# NAVSS0_SEC_PROXY_0_ALIAS64K_SEC_PROXY0_CFG_SCFG register map
Vendor: Texas Instruments
Peripheral module from a debugger description file (folder J7_AHP).
Registers are 32-bit, read-write, reset 0x0 unless marked. A register's access mark holds for its fields unless they carry their own. Offsets are as the file gives them; lines under a group give offsets from that group; [hi:lo] are bit positions; {n}, {i} and the like mark numbered series; 'fields as' and 'values as' point back to an identical list; <NAME> marks a mode.

## NAVSS0_SEC_PROXY_0_ALIAS64K_SEC_PROXY0_CFG_SCFG
0x00 ALIAS64K_SEC_PROXY0__CFG__SCFG_buffer_l
  [31:0] BASE_L — The base address for the external buffer, lower 32 bits.
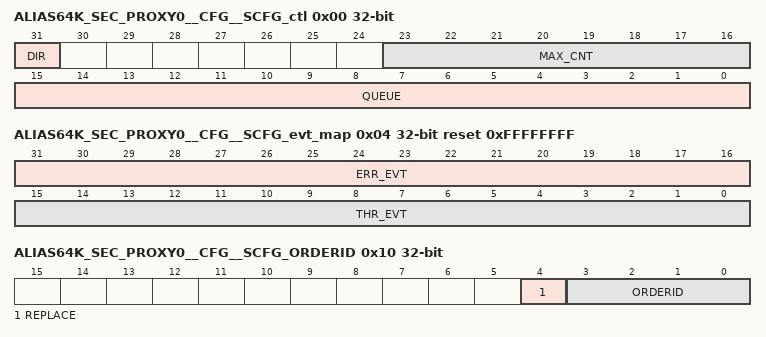
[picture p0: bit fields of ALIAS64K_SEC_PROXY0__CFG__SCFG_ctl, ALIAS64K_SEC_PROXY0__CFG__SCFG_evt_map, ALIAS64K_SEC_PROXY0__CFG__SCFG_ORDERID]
0x00 ALIAS64K_SEC_PROXY0__CFG__SCFG_ctl
  [31] DIR — Direction for the proxy thread. 0 = outbound, write only. 1 = inbound, read only.
  [23:16] MAX_CNT — Max message count allowed for an outbound proxy thread. Is not used otherwise.
  [15:0] QUEUE — Queue number in the target to use for the proxy thread. If the target base does not start at queue 0 then this is the relative queue number from that base queue.
0x04 ALIAS64K_SEC_PROXY0__CFG__SCFG_buffer_h
  [15:0] BASE_H — The base address for the external buffer, upper 16 bits.
0x04 ALIAS64K_SEC_PROXY0__CFG__SCFG_evt_map reset 0xFFFFFFFF
  [31:16] ERR_EVT — Event number for an error from the proxy thread.
  [15:0] THR_EVT — Event number for a threshold event from the proxy thread.
0x08 ALIAS64K_SEC_PROXY0__CFG__SCFG_target_l reset 0x38300000
  [31:0] BASE_L — The base address for the external target, lower 32 bits.
0x08 ALIAS64K_SEC_PROXY0__CFG__SCFG_dst
  [15:0] THREAD — The proxy thread that is the destination of messages from this outbound proxy thread, based on the queue numbers. This is ignored for inbound proxy threads.
0x0C ALIAS64K_SEC_PROXY0__CFG__SCFG_target_h
  [15:0] BASE_H — The base address for the external target, upper 16 bits.
0x10 ALIAS64K_SEC_PROXY0__CFG__SCFG_ORDERID
  [4] REPLACE — Indicates to replace the bus orderid value for the buffer access with the orderid MMR field. This allows control over the orderid value when it must be restricted due to the topology for QoS reasons. 0 = bypass and use the orderid from the source transaction for the destination transaction. 1 = use the orderid MMR field value for the destination transaction.
  [3:0] ORDERID — Defines the bus orderid value for the buffer access.
